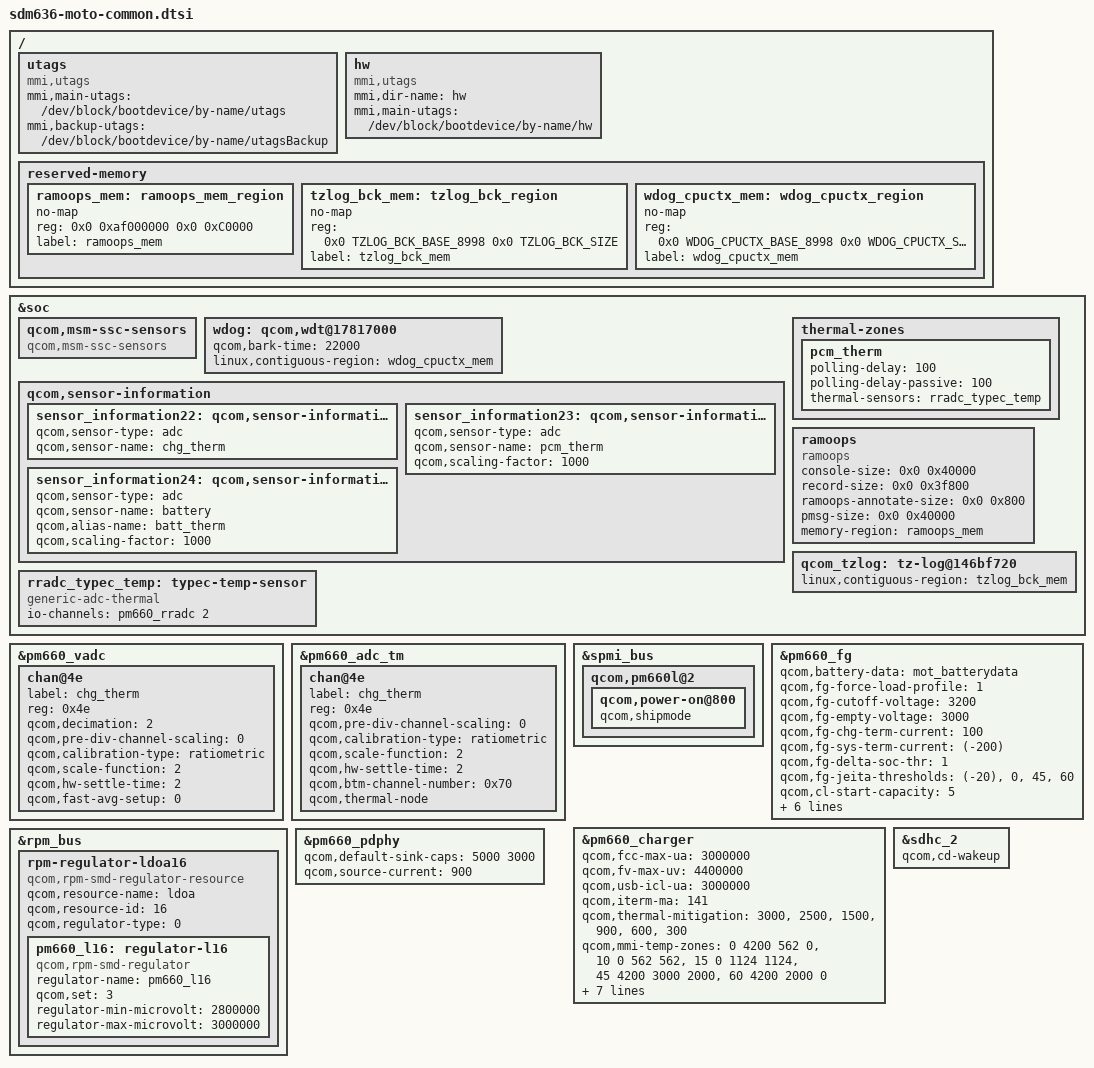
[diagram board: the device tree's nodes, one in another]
/* Copyright (c) 2016, Motorola Mobility Inc. All rights reserved.
 *
 * This program is free software; you can redistribute it and/or modify
 * it under the terms of the GNU General Public License version 2 and
 * only version 2 as published by the Free Software Foundation.
 *
 * This program is distributed in the hope that it will be useful,
 * but WITHOUT ANY WARRANTY; without even the implied warranty of
 * MERCHANTABILITY or FITNESS FOR A PARTICULAR PURPOSE.  See the
 * GNU General Public License for more details.
 */

#include "sdm636-mtp.dtsi"
#include "sdm660-moto-pinctrl.dtsi"
#include "carrier-channel-ids.dtsi"
#include <moto-mem-reserve.h>

/ {
	utags {
		compatible = "mmi,utags";
		mmi,main-utags = "/dev/block/bootdevice/by-name/utags";
		mmi,backup-utags = "/dev/block/bootdevice/by-name/utagsBackup";
	};

	hw {
		compatible = "mmi,utags";
		mmi,dir-name = "hw";
		mmi,main-utags = "/dev/block/bootdevice/by-name/hw";
	};

	reserved-memory {
		ramoops_mem: ramoops_mem_region {
			no-map;
			reg = <0x0 0xaf000000 0x0 0xC0000>;
			label = "ramoops_mem";
		};

		tzlog_bck_mem: tzlog_bck_region {
			no-map;
			reg = <0x0 TZLOG_BCK_BASE_8998
				0x0 TZLOG_BCK_SIZE>;
			label = "tzlog_bck_mem";
		};

		wdog_cpuctx_mem: wdog_cpuctx_region {
			no-map;
			reg = <0x0 WDOG_CPUCTX_BASE_8998
				0x0 WDOG_CPUCTX_SIZE_8998>;
			label = "wdog_cpuctx_mem";
		};
	};
};

&soc {
	qcom,msm-ssc-sensors {
		compatible = "qcom,msm-ssc-sensors";
	};

	wdog: qcom,wdt@17817000 {
		qcom,bark-time = <22000>;
	};

	qcom,sensor-information {
		sensor_information22: qcom,sensor-information-22 {
			qcom,sensor-type =  "adc";
			qcom,sensor-name = "chg_therm";
		};
		sensor_information23: qcom,sensor-information-23 {
			qcom,sensor-type =  "adc";
			qcom,sensor-name = "pcm_therm";
			qcom,scaling-factor = <1000>;
		};
		sensor_information24: qcom,sensor-information-24 {
			qcom,sensor-type = "adc";
			qcom,sensor-name = "battery";
			qcom,alias-name  = "batt_therm";
			qcom,scaling-factor = <1000>;
		};
	};

	rradc_typec_temp: typec-temp-sensor {
		compatible = "generic-adc-thermal";
		#thermal-sensor-cells = <0>;
		io-channels = <&pm660_rradc 2>;
		io-channel-names = "sensor-channel";
	};

	thermal-zones {
		pcm_therm {
			polling-delay = <100>; /* milliseconds */
			polling-delay-passive = <100>; /* milliseconds */
			thermal-sensors = <&rradc_typec_temp>;
		};
	};

	ramoops {
		compatible = "ramoops";
		status = "ok";

		console-size = <0x0 0x40000>;
		record-size = <0x0 0x3f800>;
		ramoops-annotate-size = <0x0 0x800>;
		pmsg-size = <0x0 0x40000>;
		memory-region = <&ramoops_mem>;
	};

	wdog: qcom,wdt@17817000 {
		qcom,bark-time = <22000>;
		linux,contiguous-region = <&wdog_cpuctx_mem>;
	};

	qcom_tzlog: tz-log@146bf720 {
		status = "okay";
		linux,contiguous-region = <&tzlog_bck_mem>;
	};
};

&pm660_vadc {
	chan@4e {
		label = "chg_therm";
		reg = <0x4e>;
		qcom,decimation = <2>;
		qcom,pre-div-channel-scaling = <0>;
		qcom,calibration-type = "ratiometric";
		qcom,scale-function = <2>;
		qcom,hw-settle-time = <2>;
		qcom,fast-avg-setup = <0>;
	};
};

&pm660_adc_tm {
	chan@4e {
		label = "chg_therm";
		reg = <0x4e>;
		qcom,pre-div-channel-scaling = <0>;
		qcom,calibration-type = "ratiometric";
		qcom,scale-function = <2>;
		qcom,hw-settle-time = <2>;
		qcom,btm-channel-number = <0x70>;
		qcom,thermal-node;
	};
};

&spmi_bus {
	qcom,pm660l@2 {
		qcom,power-on@800 {
			qcom,shipmode;
		};
	};
};

&pm660_fg {
	qcom,battery-data = <&mot_batterydata>;
	qcom,fg-force-load-profile = <1>;
	qcom,fg-cutoff-voltage = <3200>;
	qcom,fg-empty-voltage = <3000>;
	qcom,fg-chg-term-current = <100>;
	qcom,fg-sys-term-current = <(-200)>;
	qcom,fg-delta-soc-thr = <1>;
	qcom,fg-jeita-thresholds = <(-20)>, <0>, <45>, <60>;
	qcom,cl-start-capacity = <5>;
	qcom,cl-min-temp = <150>;
	qcom,cl-max-temp = <450>;
	qcom,cl-max-increment = <5>;
	qcom,cl-max-decrement = <10>;
	qcom,cl-min-limit = <200>;
	qcom,cl-max-limit = <30>;
};

&pm660_charger {
	qcom,fcc-max-ua = <3000000>;
	qcom,fv-max-uv = <4400000>;
	qcom,usb-icl-ua = <3000000>;
	qcom,iterm-ma = <141>;
	qcom,thermal-mitigation = <3000>,
				   <2500>,
				   <1500>,
				   <900>,
				   <600>,
				   <300>;
	qcom,mmi-temp-zones = <0 4200 562 0>,
				<10 0 562 562>,
				<15 0 1124 1124>,
				<45 4200 3000 2000>,
				<60 4200 2000 0>;
	qcom,enable-charging-limit;
	qcom,upper-limit-capacity = <75>;
	qcom,lower-limit-capacity = <60>;
	qcom,hvdcp-force-5v;
	qcom,typec-debounce;
	qcom,usbpd-phandle = <&pm660_pdphy>;
	qcom,source-current-ma = <900>;
};

&rpm_bus {
	rpm-regulator-ldoa16 {
		compatible = "qcom,rpm-smd-regulator-resource";
		qcom,resource-name = "ldoa";
		qcom,resource-id = <16>;
		qcom,regulator-type = <0>;
		status = "okay";
		pm660_l16: regulator-l16 {
			compatible = "qcom,rpm-smd-regulator";
			regulator-name = "pm660_l16";
			qcom,set = <3>;
			regulator-min-microvolt = <2800000>;
			regulator-max-microvolt = <3000000>;
			status = "okay";
		};
	};
};

&pm660_pdphy {
	qcom,default-sink-caps = <5000 3000>; /* 5V @ 3A */
	qcom,source-current = <900>;
};

&sdhc_2 {
       qcom,cd-wakeup;
};
